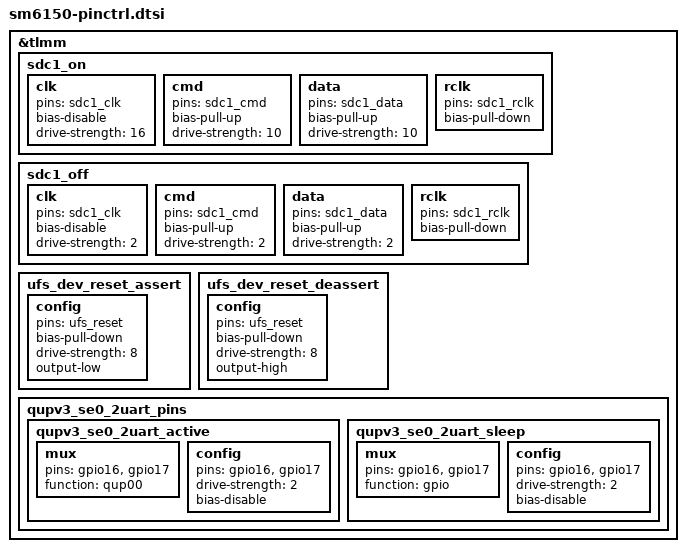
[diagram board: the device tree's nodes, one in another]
// SPDX-License-Identifier: BSD-3-Clause
/*
 * Copyright (c) 2025 Qualcomm Innovation Center, Inc. All rights reserved.
 */

&tlmm {
	sdc1_on: sdc1_on {
		clk {
			pins = "sdc1_clk";
			bias-disable;
			drive-strength = <16>;
		};

		cmd {
			pins = "sdc1_cmd";
			bias-pull-up;
			drive-strength = <10>;
		};

		data {
			pins = "sdc1_data";
			bias-pull-up;
			drive-strength = <10>;
		};

		rclk {
			pins = "sdc1_rclk";
			bias-pull-down;
		};
	};

	sdc1_off: sdc1_off {
		clk {
			pins = "sdc1_clk";
			bias-disable;
			drive-strength = <2>;
		};

		cmd {
			pins = "sdc1_cmd";
			bias-pull-up;
			drive-strength = <2>;
		};

		data {
			pins = "sdc1_data";
			bias-pull-up;
			drive-strength = <2>;
		};

		rclk {
			pins = "sdc1_rclk";
			bias-pull-down;
		};
	};

	ufs_dev_reset_assert: ufs_dev_reset_assert {
		config {
			pins = "ufs_reset";
			bias-pull-down;
			/*
			 * default: pull down
			 * UFS_RESET driver strengths are having
			 * different values/steps compared to typical
			 * GPIO drive strengths.
			 *
			 * Following table clarifies:
			 *
			 * HDRV value | UFS_RESET | Typical GPIO
			 *   (dec)    |   (mA)    |    (mA)
			 *     0      |   0.8     |    2
			 *     1      |   1.55    |    4
			 *     2      |   2.35    |    6
			 *     3      |   3.1     |    8
			 *     4      |   3.9     |    10
			 *     5      |   4.65    |    12
			 *     6      |   5.4     |    14
			 *     7      |   6.15    |    16
			 *
			 * POR value for UFS_RESET HDRV is 3 which means
			 * 3.1mA and we want to use that. Hence just
			 * specify 8mA to "drive-strength" binding and
			 * that should result into writing 3 to HDRV
			 * field.
			 */
			drive-strength = <8>;   /* default: 3.1 mA */
			output-low; /* active low reset */
		};
	};

	ufs_dev_reset_deassert: ufs_dev_reset_deassert {
		config {
			pins = "ufs_reset";
			bias-pull-down;
			/*
			 * default: pull down
			 * default: 3.1 mA
			 * check comments under ufs_dev_reset_assert
			 */
			drive-strength = <8>;
			output-high; /* active low reset */
		};
	};

	qupv3_se0_2uart_pins: qupv3_se0_2uart_pins {
		qupv3_se0_2uart_active: qupv3_se0_2uart_active {
			mux {
				pins = "gpio16", "gpio17";
				function = "qup00";
			};

			config {
				pins = "gpio16", "gpio17";
				drive-strength = <2>;
				bias-disable;
			};
		};

		qupv3_se0_2uart_sleep: qupv3_se0_2uart_sleep {
			mux {
				pins = "gpio16", "gpio17";
				function = "gpio";
			};

			config {
				pins = "gpio16", "gpio17";
				drive-strength = <2>;
				bias-disable;
			};
		};
	};
};
